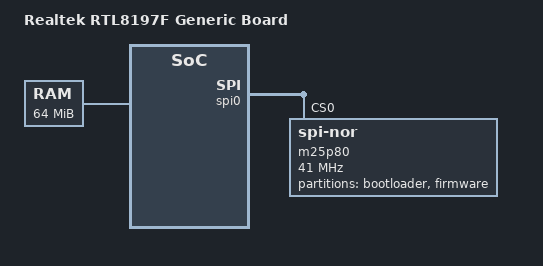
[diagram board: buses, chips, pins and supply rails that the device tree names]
// SPDX-License-Identifier: GPL-2.0
/dts-v1/;

#include "RTL8197F.dtsi"

/ {
	compatible = "realtek,rtl8197f-generic", "realtek,rtl8197f-soc";
	model = "Realtek RTL8197F Generic Board";

	memory {
		device_type = "memory";
		reg = <0x0 0x4000000>;
	};

	chosen {
		bootargs = "console=ttyS0,38400";
	};
};

&spi0 {
	status = "okay";

	m25p80@0 {
		#address-cells = <1>;
		#size-cells = <1>;
		compatible = "jedec,spi-nor";
		reg = <0>;
		spi-max-frequency = <41000000>;

		partition@0 {
			label = "bootloader";
			reg = <0x0 0x20000>;
			read-only;
		};

		partition@20000 {
			label = "firmware";
			reg = <0x20000 0x3E0000>;
		};
	};
};
